# PIC18LF6520 register map
Vendor: Microchip
Architecture 18xxxx. Special function registers and configuration words.
Registers are 8-bit, read-write, no defined reset value unless marked. A register's access mark holds for its fields unless they carry their own. Addresses are absolute, and some are shared; only a register's first bit layout is shown; lines under a group give offsets from that group; [hi:lo] are bit positions; {n}, {i} and the like mark numbered series; 'fields as' and 'values as' point back to an identical list; <NAME> marks a mode.

## Further device data
pins=1: RE1/WR; 2: RE0/RD; 3: RG0/CCP3; 4: RG1/TX2/CK2; 5: RG2/RX2/DT2; 6: RG3/CCP4; 7: MCLR/Vpp; 8: RG4/CCP5; 9: Vss; 10: Vdd; 11: RF7/SS; 12: RF6/AN11; 13: RF5/AN10/CVref; 14: RF4/AN9; 15: RF3/AN8; 16: RF2/AN7/C1OUT; 17: RF1/AN6/C2OUT; 18: RF0/AN5; 19: Avdd; 20: Avss; 21: RA3/AN3/Vref+; 22: RA2/AN2/Vref-; 23: RA1/AN1; 24: RA0/AN0; 25: Vss; 26: Vdd; 27: RA5/AN4/LVDIN; 28: RA4/T0CKI; 29: RC1/T1OSI/CCP2; 30: RC0/T1OSO/T13CKI; 31: RC6/TX1/CK1; 32: RC7/RX1/DT1; 33: RC2/CCP1; 34: RC3/SCK/SCL; 35: RC4/SDI/SDA; 36: RC5/SDO; 37: RB7/KBI3/PGD; 38: Vdd; 39: OSC1/CLKI; 40: OSC2/CLKO/RA6; 41: Vss; 42: RB6/KBI2/PGC; 43: RB5/KBI1/PGM; 44: RB4/KBI0; 45: RB3/INT3; 46: RB2/INT2; 47: RB1/INT1; 48: RB0/INT0; 49: RD7/PSP7; 50: RD6/PSP6; 51: RD5/PSP5; 52: RD4/PSP4; 53: RD3/PSP3; 54: RD2/PSP2; 55: RD1/PSP1; 56: Vss; 57: Vdd; 58: RD0/PSP0; 59: RE7/CCP2; 60: RE6; 61: RE5; 62: RE4; 63: RE3; 64: RE2/CS

## CONFIG — Configuration words, addresses in ProgramSpace
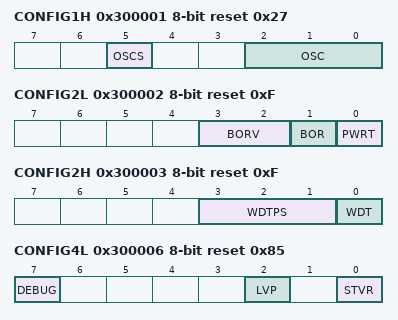
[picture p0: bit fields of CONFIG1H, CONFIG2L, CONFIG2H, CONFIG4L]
0x300001 CONFIG1H reset 0x27
  [5] OSCS — Oscillator System Clock Switch Enable bit
    1=OFF (Oscillator system clock switch option is disabled (main oscillator is source)); 0=ON (Timer1 Oscillator system clock switch option is enabled (oscillator switching is enabled))
  [2:0] OSC — Oscillator Selection bits
    7=RCIO (RC oscillator w/ OSC2 configured as RA6); 6=HSPLL (HS oscillator with PLL enabled; clock frequency = (4 x FOSC)); 5=ECIO (EC oscillator w/ OSC2 configured as RA6); 4=EC (EC oscillator w/ OSC2 configured as divide-by-4 clock output); 3=RC (RC oscillator w/ OSC2 configured as divide-by-4 clock output); 2=HS (HS oscillator); 1=XT (XT oscillator); 0=LP (LP oscillator)
0x300002 CONFIG2L reset 0xF
  [3:2] BORV — Brown-out Reset Voltage bits
    3=VBOR set to 2.5V; 2=VBOR set to 2.7V; 1=VBOR set to 4.2V; 0=VBOR set to 4.5V
  [1] BOR — Brown-out Reset Enable bit
    1=ON (Brown-out Reset enabled); 0=OFF (Brown-out Reset disabled)
  [0] PWRT — Power-up Timer Enable bit
    1=OFF (PWRT disabled); 0=ON (PWRT enabled)
0x300003 CONFIG2H reset 0xF
  [3:1] WDTPS — Watchdog Timer Postscale Select bits
    7=1:128; 6=1:64; 5=1:32; 4=1:16; 3=1:8; 2=1:4; 1=1:2; 0=1:1
  [0] WDT — Watchdog Timer Enable bit
    1=ON (WDT enabled); 0=OFF (WDT disabled (control is placed on the SWDTEN bit))
0x300004 CONFIG3L reset 0x83
0x300005 CONFIG3H reset 0x3
  [0] CCP2MUX — CCP2 Mux bit
    1=ON (CCP2 input/output is multiplexed with RC1); 0=OFF (CCP2 input/output is multiplexed with RE7)
0x300006 CONFIG4L reset 0x85
  [7] DEBUG — Background Debugger Enable bit
    1=OFF (Background debugger disabled. RB6 and RB7 configured as general purpose I/O pins.); 0=ON (Background debugger enabled. RB6 and RB7 are dedicated to In-Circuit Debug.)
  [2] LVP — Low-Voltage ICSP Enable bit
    1=ON (Low-voltage ICSP enabled); 0=OFF (Low-voltage ICSP disabled)
  [0] STVR — Stack Full/Underflow Reset Enable bit
    1=ON (Stack full/underflow will cause Reset); 0=OFF (Stack full/underflow will not cause Reset)
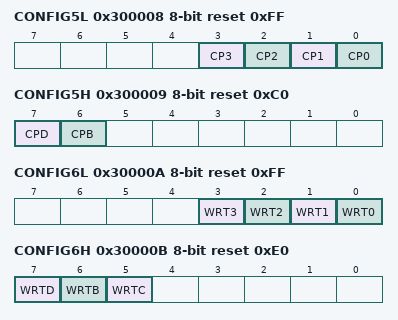
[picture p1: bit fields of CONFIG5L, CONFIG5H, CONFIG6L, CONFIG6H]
0x300008 CONFIG5L reset 0xFF
  [3] CP3 — Code Protection bit
    1=OFF (Block 3 (006000-007FFFh) not code-protected); 0=ON (Block 3 (006000-007FFFh) code-protected)
  [2] CP2 — Code Protection bit
    1=OFF (Block 2 (004000-005FFFh) not code-protected); 0=ON (Block 2 (004000-005FFFh) code-protected)
  [1] CP1 — Code Protection bit
    1=OFF (Block 1 (002000-003FFFh) not code-protected); 0=ON (Block 1 (002000-003FFFh) code-protected)
  [0] CP0 — Code Protection bit
    1=OFF (Block 0 (000800-001FFFh) not code-protected); 0=ON (Block 0 (000800-001FFFh) code-protected)
0x300009 CONFIG5H reset 0xC0
  [7] CPD — Data EEPROM Code Protection bit
    1=OFF (Data EEPROM not code-protected); 0=ON (Data EEPROM code-protected)
  [6] CPB — Boot Block Code Protection bit
    1=OFF (Boot Block (000000-0007FFh) not code-protected); 0=ON (Boot Block (000000-0007FFh) code-protected)
0x30000A CONFIG6L reset 0xFF
  [3] WRT3 — Write Protection bit
    1=OFF (Block 3 (006000-007FFFh) not write-protected); 0=ON (Block 3 (006000-007FFFh) write-protected)
  [2] WRT2 — Write Protection bit
    1=OFF (Block 2 (004000-005FFFh) not write-protected); 0=ON (Block 2 (004000-005FFFh) write-protected)
  [1] WRT1 — Write Protection bit
    1=OFF (Block 1 (002000-003FFFh) not write-protected); 0=ON (Block 1 (002000-003FFFh) write-protected)
  [0] WRT0 — Write Protection bit
    1=OFF (Block 0 (000800-001FFFh) not write-protected); 0=ON (Block 0 (000800-001FFFh) write-protected)
0x30000B CONFIG6H reset 0xE0
  [7] WRTD — Data EEPROM Write Protection bit
    1=OFF (Data EEPROM not write-protected); 0=ON (Data EEPROM write-protected)
  [6] WRTB — Boot Block Write Protection bit
    1=OFF (Boot Block (000000-0007FFh) not write-protected); 0=ON (Boot Block (000000-0007FFh) write-protected)
  [5] WRTC — Configuration Register Write Protection bit
    1=OFF (Configuration registers (300000-3000FFh) not write-protected); 0=ON (Configuration registers (300000-3000FFh) write-protected)
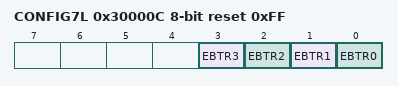
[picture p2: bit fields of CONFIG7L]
0x30000C CONFIG7L reset 0xFF
  [3] EBTR3 — Table Read Protection bit
    1=OFF (Block 3 (006000-007FFFh) not protected from table reads executed in other blocks); 0=ON (Block 3 (006000-007FFFh) protected from table reads executed in other blocks)
  [2] EBTR2 — Table Read Protection bit
    1=OFF (Block 2 (004000-005FFFh) not protected from table reads executed in other blocks); 0=ON (Block 2 (004000-005FFFh) protected from table reads executed in other blocks)
  [1] EBTR1 — Table Read Protection bit
    1=OFF (Block 1 (002000-003FFFh) not protected from table reads executed in other blocks); 0=ON (Block 1 (002000-003FFFh) protected from table reads executed in other blocks)
  [0] EBTR0 — Table Read Protection bit
    1=OFF (Block 0 (000800-001FFFh) not protected from table reads executed in other blocks); 0=ON (Block 0 (000800-001FFFh) protected from table reads executed in other blocks)
0x30000D CONFIG7H reset 0x40
  [6] EBTRB — Boot Block Table Read Protection bit
    1=OFF (Boot Block (000000-0007FFh) not protected from table reads executed in other blocks); 0=ON (Boot Block (000000-0007FFh) protected from table reads executed in other blocks)
